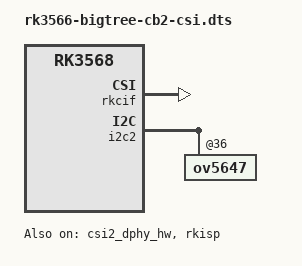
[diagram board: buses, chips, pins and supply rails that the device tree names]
/dts-v1/;
/plugin/;


#include <dt-bindings/gpio/gpio.h>
#include <dt-bindings/pinctrl/rockchip.h>
#include <dt-bindings/power/rk3568-power.h>

/ {	
	compatible = "rockchip,rk3568";
	
	fragment@0 {
		target = <&csi2_dphy_hw>;
		
		__overlay__ {
			status = "okay";
		};
	};
	
	fragment@1 {
		target = <&rkisp>;
		
		__overlay__ {
			status = "okay";		
		};
	};
	
	fragment@2 {
		target = <&rkisp_mmu>;
		
		__overlay__ {
			
			status = "okay";
			};
	};
	
	fragment@3 {
		target = <&rkcif_mmu>;
		
		__overlay__ {
			status = "okay";
		};
	};
	
	fragment@4 {
		target = <&rkcif>;
		
		__overlay__ {
			status = "okay";		
		};
	};
	
	fragment@5 {
		target = <&i2c2>;
		
		__overlay__ {
			
			status = "okay";
			ov5647@36 {
				status = "okay";
	       
			};
		};

	};
		
};
